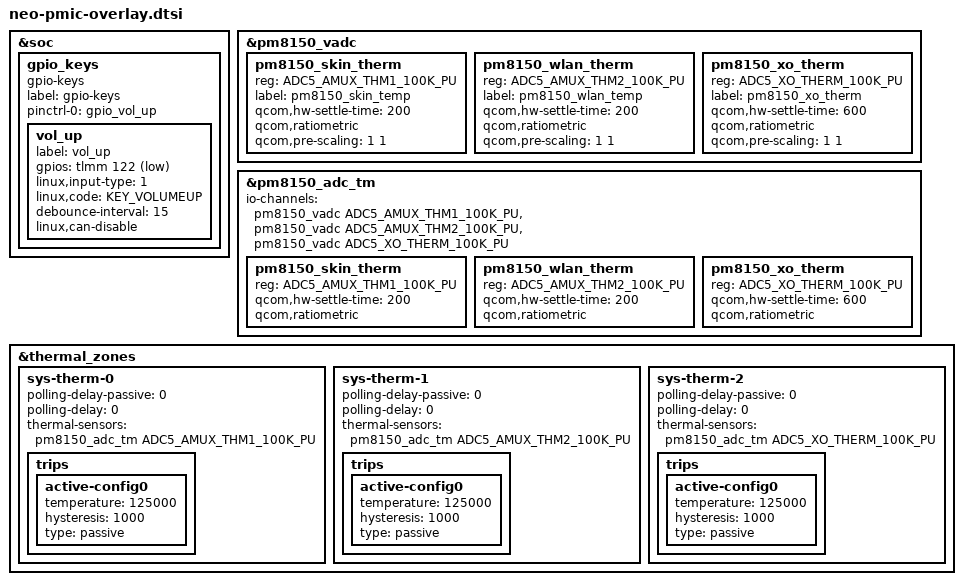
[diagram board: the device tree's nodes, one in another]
#include <dt-bindings/gpio/gpio.h>
#include <dt-bindings/pinctrl/qcom,pmic-gpio.h>
#include <dt-bindings/iio/qcom,spmi-vadc.h>

#include "pm8150.dtsi"

&soc {
	gpio_keys {
		compatible = "gpio-keys";
		label = "gpio-keys";
		pinctrl-names = "default";
		pinctrl-0 = <&gpio_vol_up>;

		vol_up {
			label = "vol_up";
			gpios = <&tlmm 122 GPIO_ACTIVE_LOW>;
			linux,input-type = <1>;
			linux,code = <KEY_VOLUMEUP>;
			debounce-interval = <15>;
			linux,can-disable;
		};
	};
};

&pm8150_vadc {
	pm8150_skin_therm {
		reg = <ADC5_AMUX_THM1_100K_PU>;
		label = "pm8150_skin_temp";
		qcom,hw-settle-time = <200>;
		qcom,ratiometric;
		qcom,pre-scaling = <1 1>;
	};

	pm8150_wlan_therm {
		reg = <ADC5_AMUX_THM2_100K_PU>;
		label = "pm8150_wlan_temp";
		qcom,hw-settle-time = <200>;
		qcom,ratiometric;
		qcom,pre-scaling = <1 1>;
	};

	pm8150_xo_therm {
		reg = <ADC5_XO_THERM_100K_PU>;
		label = "pm8150_xo_therm";
		qcom,hw-settle-time = <600>;
		qcom,ratiometric;
		qcom,pre-scaling = <1 1>;
	};
};

&pm8150_adc_tm {
	io-channels = <&pm8150_vadc ADC5_AMUX_THM1_100K_PU>,
			<&pm8150_vadc ADC5_AMUX_THM2_100K_PU>,
			<&pm8150_vadc ADC5_XO_THERM_100K_PU>;

	pm8150_skin_therm {
		reg = <ADC5_AMUX_THM1_100K_PU>;
		qcom,hw-settle-time = <200>;
		qcom,ratiometric;
	};

	pm8150_wlan_therm {
		reg = <ADC5_AMUX_THM2_100K_PU>;
		qcom,hw-settle-time = <200>;
		qcom,ratiometric;
	};

	pm8150_xo_therm {
		reg = <ADC5_XO_THERM_100K_PU>;
		qcom,hw-settle-time = <600>;
		qcom,ratiometric;
	};
};

&thermal_zones {
	sys-therm-0 {
		polling-delay-passive = <0>;
		polling-delay = <0>;
		thermal-sensors = <&pm8150_adc_tm ADC5_AMUX_THM1_100K_PU>;
		trips {
			active-config0 {
				temperature = <125000>;
				hysteresis = <1000>;
				type = "passive";
			};
		};
	};

	sys-therm-1 {
		polling-delay-passive = <0>;
		polling-delay = <0>;
		thermal-sensors = <&pm8150_adc_tm ADC5_AMUX_THM2_100K_PU>;
		trips {
			active-config0 {
				temperature = <125000>;
				hysteresis = <1000>;
				type = "passive";
			};
		};
	};

	sys-therm-2 {
		polling-delay-passive = <0>;
		polling-delay = <0>;
		thermal-sensors = <&pm8150_adc_tm ADC5_XO_THERM_100K_PU>;
		trips {
			active-config0 {
				temperature = <125000>;
				hysteresis = <1000>;
				type = "passive";
			};
		};
	};
};
